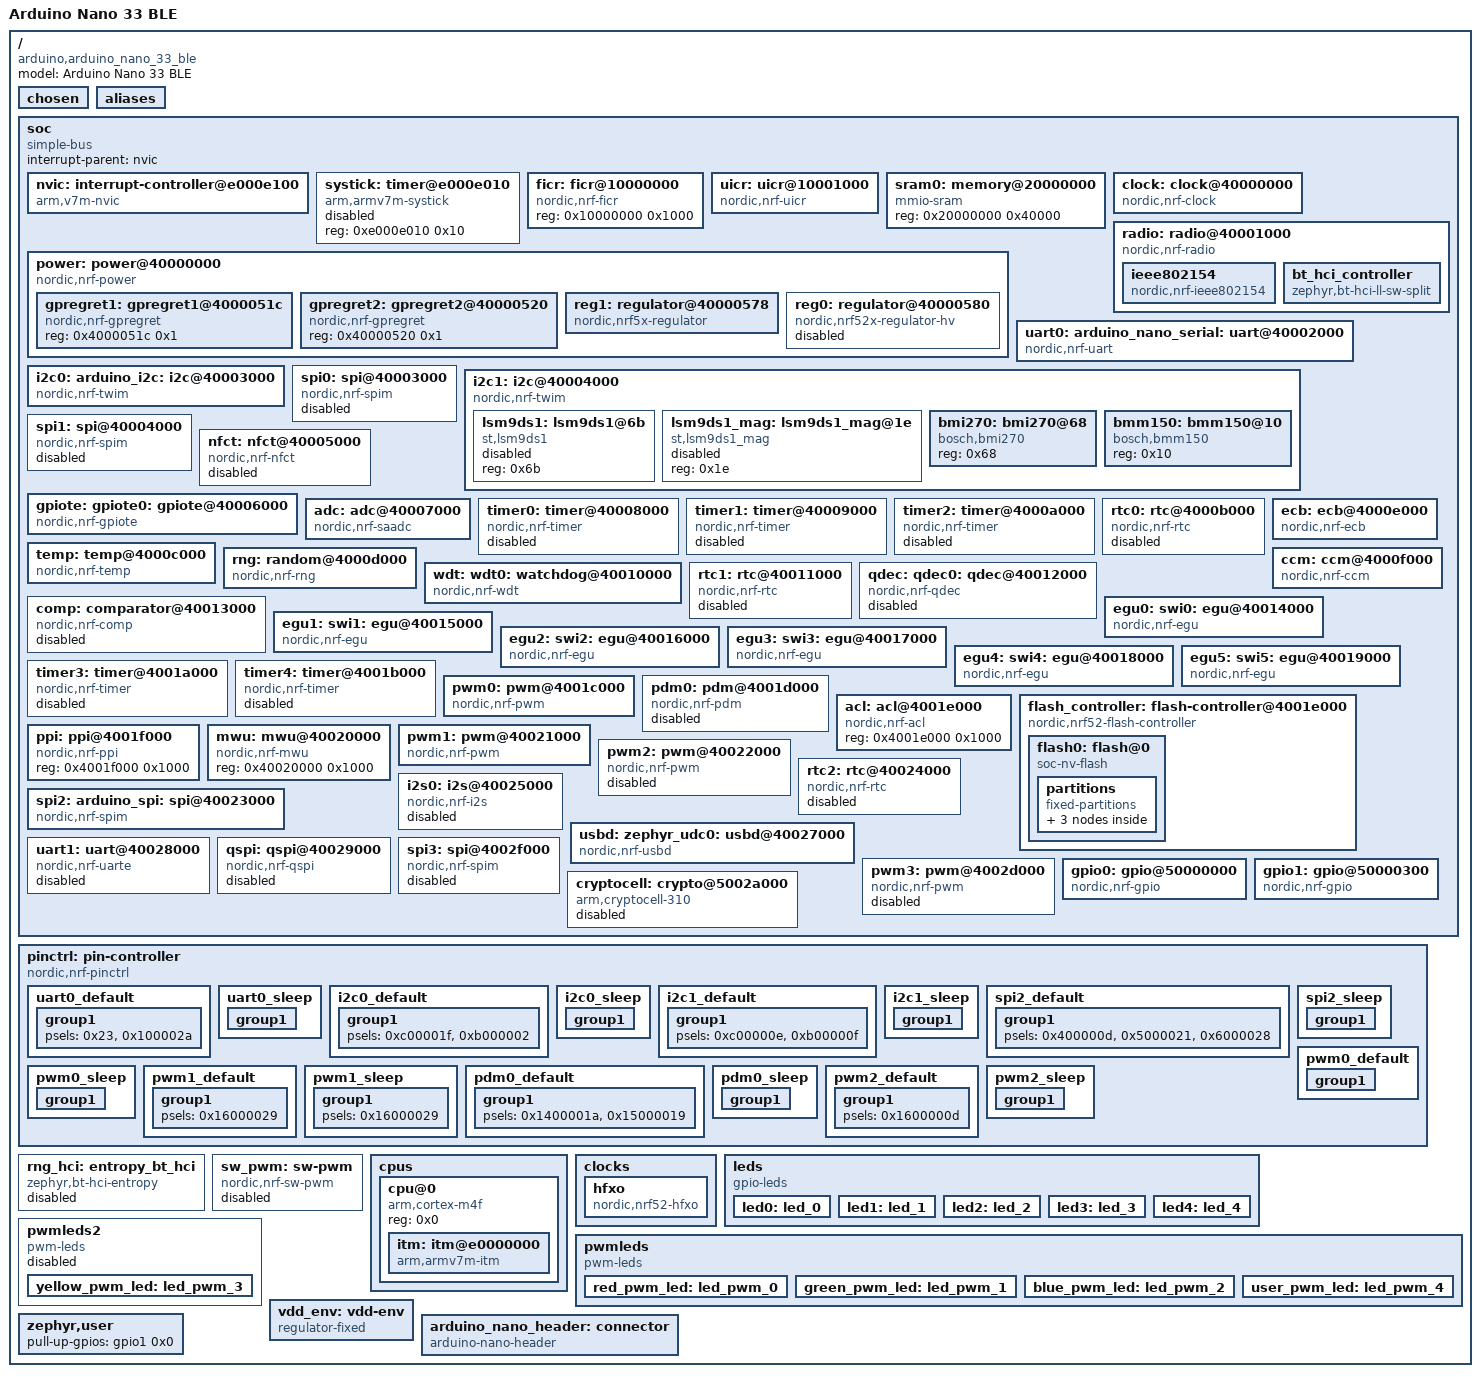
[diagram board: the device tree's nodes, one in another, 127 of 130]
/dts-v1/;

/* node '/' defined in zephyr\dts\common\skeleton.dtsi:9 */
/ {
	#address-cells = < 0x1 >;                   /* in zephyr\dts\common\skeleton.dtsi:10 */
	#size-cells = < 0x1 >;                      /* in zephyr\dts\common\skeleton.dtsi:11 */
	model = "Arduino Nano 33 BLE";              /* in zephyr\boards\arduino\nano_33_ble\arduino_nano_33_ble.dts:13 */
	compatible = "arduino,arduino_nano_33_ble"; /* in zephyr\boards\arduino\nano_33_ble\arduino_nano_33_ble.dts:14 */

	/* node '/chosen' defined in zephyr\dts\common\skeleton.dtsi:13 */
	chosen {
		zephyr,bt-hci = &bt_hci_controller;          /* in zephyr\dts\arm\nordic\nrf52840.dtsi:10 */
		zephyr,entropy = &rng;                       /* in zephyr\dts\arm\nordic\nrf52840.dtsi:11 */
		zephyr,flash-controller = &flash_controller; /* in zephyr\dts\arm\nordic\nrf52840.dtsi:12 */
		zephyr,console = &uart0;                     /* in zephyr\boards\arduino\nano_33_ble\arduino_nano_33_ble-common.dtsi:9 */
		zephyr,shell-uart = &uart0;                  /* in zephyr\boards\arduino\nano_33_ble\arduino_nano_33_ble-common.dtsi:10 */
		zephyr,uart-mcumgr = &uart0;                 /* in zephyr\boards\arduino\nano_33_ble\arduino_nano_33_ble-common.dtsi:11 */
		zephyr,bt-mon-uart = &uart0;                 /* in zephyr\boards\arduino\nano_33_ble\arduino_nano_33_ble-common.dtsi:12 */
		zephyr,bt-c2h-uart = &uart0;                 /* in zephyr\boards\arduino\nano_33_ble\arduino_nano_33_ble-common.dtsi:13 */
		zephyr,sram = &sram0;                        /* in zephyr\boards\arduino\nano_33_ble\arduino_nano_33_ble-common.dtsi:14 */
		zephyr,flash = &flash0;                      /* in zephyr\boards\arduino\nano_33_ble\arduino_nano_33_ble-common.dtsi:15 */
		zephyr,code-partition = &code_partition;     /* in zephyr\boards\arduino\nano_33_ble\arduino_nano_33_ble-common.dtsi:16 */
		zephyr,ieee802154 = &ieee802154;             /* in zephyr\boards\arduino\nano_33_ble\arduino_nano_33_ble-common.dtsi:17 */
	};

	/* node '/aliases' defined in zephyr\dts\common\skeleton.dtsi:15 */
	aliases {
		led0 = &led0;                   /* in zephyr\boards\arduino\nano_33_ble\arduino_nano_33_ble-common.dtsi:100 */
		led1 = &led1;                   /* in zephyr\boards\arduino\nano_33_ble\arduino_nano_33_ble-common.dtsi:101 */
		led2 = &led2;                   /* in zephyr\boards\arduino\nano_33_ble\arduino_nano_33_ble-common.dtsi:102 */
		led3 = &led3;                   /* in zephyr\boards\arduino\nano_33_ble\arduino_nano_33_ble-common.dtsi:103 */
		led4 = &led4;                   /* in zephyr\boards\arduino\nano_33_ble\arduino_nano_33_ble-common.dtsi:104 */
		pwm-led0 = &red_pwm_led;        /* in zephyr\boards\arduino\nano_33_ble\arduino_nano_33_ble-common.dtsi:105 */
		pwm-led1 = &green_pwm_led;      /* in zephyr\boards\arduino\nano_33_ble\arduino_nano_33_ble-common.dtsi:106 */
		pwm-led2 = &blue_pwm_led;       /* in zephyr\boards\arduino\nano_33_ble\arduino_nano_33_ble-common.dtsi:107 */
		pwm-led3 = &yellow_pwm_led;     /* in zephyr\boards\arduino\nano_33_ble\arduino_nano_33_ble-common.dtsi:108 */
		pwm-led4 = &user_pwm_led;       /* in zephyr\boards\arduino\nano_33_ble\arduino_nano_33_ble-common.dtsi:109 */
		red-pwm-led = &red_pwm_led;     /* in zephyr\boards\arduino\nano_33_ble\arduino_nano_33_ble-common.dtsi:110 */
		green-pwm-led = &green_pwm_led; /* in zephyr\boards\arduino\nano_33_ble\arduino_nano_33_ble-common.dtsi:111 */
		blue-pwm-led = &blue_pwm_led;   /* in zephyr\boards\arduino\nano_33_ble\arduino_nano_33_ble-common.dtsi:112 */
		spi = &spi2;                    /* in zephyr\boards\arduino\nano_33_ble\arduino_nano_33_ble-common.dtsi:113 */
		watchdog0 = &wdt0;              /* in zephyr\boards\arduino\nano_33_ble\arduino_nano_33_ble-common.dtsi:114 */
		accel0 = &lsm9ds1;              /* in zephyr\boards\arduino\nano_33_ble\arduino_nano_33_ble-common.dtsi:115 */
	};

	/* node '/soc' defined in zephyr\dts\arm\armv7-m.dtsi:6 */
	soc {
		#address-cells = < 0x1 >;     /* in zephyr\dts\arm\armv7-m.dtsi:7 */
		#size-cells = < 0x1 >;        /* in zephyr\dts\arm\armv7-m.dtsi:8 */
		interrupt-parent = < &nvic >; /* in zephyr\dts\arm\armv7-m.dtsi:10 */
		ranges;                       /* in zephyr\dts\arm\armv7-m.dtsi:11 */
		compatible = "simple-bus";    /* in zephyr\dts\arm\nordic\nrf52840_qiaa.dtsi:30 */

		/* node '/soc/interrupt-controller@e000e100' defined in zephyr\dts\arm\armv7-m.dtsi:13 */
		nvic: interrupt-controller@e000e100 {
			#address-cells = < 0x1 >;            /* in zephyr\dts\arm\armv7-m.dtsi:14 */
			compatible = "arm,v7m-nvic";         /* in zephyr\dts\arm\armv7-m.dtsi:15 */
			reg = < 0xe000e100 0xc00 >;          /* in zephyr\dts\arm\armv7-m.dtsi:16 */
			interrupt-controller;                /* in zephyr\dts\arm\armv7-m.dtsi:17 */
			#interrupt-cells = < 0x2 >;          /* in zephyr\dts\arm\armv7-m.dtsi:18 */
			arm,num-irq-priority-bits = < 0x3 >; /* in zephyr\dts\arm\nordic\nrf52840.dtsi:582 */
			phandle = < 0x1 >;                   /* in zephyr\dts\arm\armv7-m.dtsi:10 */
		};

		/* node '/soc/timer@e000e010' defined in zephyr\dts\arm\armv7-m.dtsi:21 */
		systick: timer@e000e010 {
			compatible = "arm,armv7m-systick"; /* in zephyr\dts\arm\armv7-m.dtsi:22 */
			reg = < 0xe000e010 0x10 >;         /* in zephyr\dts\arm\armv7-m.dtsi:23 */
			status = "disabled";               /* in zephyr\dts\arm\nordic\nrf52840.dtsi:587 */
		};

		/* node '/soc/ficr@10000000' defined in zephyr\dts\arm\nordic\nrf52840.dtsi:44 */
		ficr: ficr@10000000 {
			compatible = "nordic,nrf-ficr"; /* in zephyr\dts\arm\nordic\nrf52840.dtsi:45 */
			reg = < 0x10000000 0x1000 >;    /* in zephyr\dts\arm\nordic\nrf52840.dtsi:46 */
			#nordic,ficr-cells = < 0x1 >;   /* in zephyr\dts\arm\nordic\nrf52840.dtsi:47 */
			status = "okay";                /* in zephyr\dts\arm\nordic\nrf52840.dtsi:48 */
		};

		/* node '/soc/uicr@10001000' defined in zephyr\dts\arm\nordic\nrf52840.dtsi:51 */
		uicr: uicr@10001000 {
			compatible = "nordic,nrf-uicr"; /* in zephyr\dts\arm\nordic\nrf52840.dtsi:52 */
			reg = < 0x10001000 0x1000 >;    /* in zephyr\dts\arm\nordic\nrf52840.dtsi:53 */
			status = "okay";                /* in zephyr\dts\arm\nordic\nrf52840.dtsi:54 */
			gpio-as-nreset;                 /* in zephyr\boards\arduino\nano_33_ble\arduino_nano_33_ble-common.dtsi:200 */
		};

		/* node '/soc/memory@20000000' defined in zephyr\dts\arm\nordic\nrf52840.dtsi:57 */
		sram0: memory@20000000 {
			compatible = "mmio-sram";            /* in zephyr\dts\arm\nordic\nrf52840.dtsi:58 */
			#address-cells = < 0x1 >;            /* in zephyr\dts\arm\nordic\nrf52840.dtsi:59 */
			#size-cells = < 0x1 >;               /* in zephyr\dts\arm\nordic\nrf52840.dtsi:60 */
			reg = < 0x20000000 0x40000 >;        /* in zephyr\dts\arm\nordic\nrf52840_qiaa.dtsi:15 */
			ranges = < 0x0 0x20000000 0x40000 >; /* in zephyr\dts\arm\nordic\nrf52840_qiaa.dtsi:16 */
		};

		/* node '/soc/clock@40000000' defined in zephyr\dts\arm\nordic\nrf52840.dtsi:63 */
		clock: clock@40000000 {
			compatible = "nordic,nrf-clock"; /* in zephyr\dts\arm\nordic\nrf52840.dtsi:64 */
			reg = < 0x40000000 0x1000 >;     /* in zephyr\dts\arm\nordic\nrf52840.dtsi:65 */
			interrupts = < 0x0 0x1 >;        /* in zephyr\dts\arm\nordic\nrf52840.dtsi:66 */
			status = "okay";                 /* in zephyr\dts\arm\nordic\nrf52840.dtsi:67 */
		};

		/* node '/soc/power@40000000' defined in zephyr\dts\arm\nordic\nrf52840.dtsi:70 */
		power: power@40000000 {
			compatible = "nordic,nrf-power"; /* in zephyr\dts\arm\nordic\nrf52840.dtsi:71 */
			reg = < 0x40000000 0x1000 >;     /* in zephyr\dts\arm\nordic\nrf52840.dtsi:72 */
			interrupts = < 0x0 0x1 >;        /* in zephyr\dts\arm\nordic\nrf52840.dtsi:73 */
			status = "okay";                 /* in zephyr\dts\arm\nordic\nrf52840.dtsi:74 */
			#address-cells = < 0x1 >;        /* in zephyr\dts\arm\nordic\nrf52840.dtsi:75 */
			#size-cells = < 0x1 >;           /* in zephyr\dts\arm\nordic\nrf52840.dtsi:76 */

			/* node '/soc/power@40000000/gpregret1@4000051c' defined in zephyr\dts\arm\nordic\nrf52840.dtsi:78 */
			gpregret1: gpregret1@4000051c {
				#address-cells = < 0x1 >;           /* in zephyr\dts\arm\nordic\nrf52840.dtsi:79 */
				#size-cells = < 0x1 >;              /* in zephyr\dts\arm\nordic\nrf52840.dtsi:80 */
				compatible = "nordic,nrf-gpregret"; /* in zephyr\dts\arm\nordic\nrf52840.dtsi:81 */
				reg = < 0x4000051c 0x1 >;           /* in zephyr\dts\arm\nordic\nrf52840.dtsi:82 */
				status = "okay";                    /* in zephyr\dts\arm\nordic\nrf52840.dtsi:83 */
			};

			/* node '/soc/power@40000000/gpregret2@40000520' defined in zephyr\dts\arm\nordic\nrf52840.dtsi:86 */
			gpregret2: gpregret2@40000520 {
				#address-cells = < 0x1 >;           /* in zephyr\dts\arm\nordic\nrf52840.dtsi:87 */
				#size-cells = < 0x1 >;              /* in zephyr\dts\arm\nordic\nrf52840.dtsi:88 */
				compatible = "nordic,nrf-gpregret"; /* in zephyr\dts\arm\nordic\nrf52840.dtsi:89 */
				reg = < 0x40000520 0x1 >;           /* in zephyr\dts\arm\nordic\nrf52840.dtsi:90 */
				status = "okay";                    /* in zephyr\dts\arm\nordic\nrf52840.dtsi:91 */
			};

			/* node '/soc/power@40000000/regulator@40000578' defined in zephyr\dts\arm\nordic\nrf52840.dtsi:94 */
			reg1: regulator@40000578 {
				compatible = "nordic,nrf5x-regulator"; /* in zephyr\dts\arm\nordic\nrf52840.dtsi:95 */
				reg = < 0x40000578 0x1 >;              /* in zephyr\dts\arm\nordic\nrf52840.dtsi:96 */
				regulator-name = "REG1";               /* in zephyr\dts\arm\nordic\nrf52840.dtsi:97 */
				regulator-initial-mode = < 0x0 >;      /* in zephyr\dts\arm\nordic\nrf52840.dtsi:98 */
			};

			/* node '/soc/power@40000000/regulator@40000580' defined in zephyr\dts\arm\nordic\nrf52840_qiaa.dtsi:20 */
			reg0: regulator@40000580 {
				compatible = "nordic,nrf52x-regulator-hv"; /* in zephyr\dts\arm\nordic\nrf52840_qiaa.dtsi:21 */
				reg = < 0x40000580 0x1 >;                  /* in zephyr\dts\arm\nordic\nrf52840_qiaa.dtsi:22 */
				regulator-name = "REG0";                   /* in zephyr\dts\arm\nordic\nrf52840_qiaa.dtsi:23 */
				status = "disabled";                       /* in zephyr\dts\arm\nordic\nrf52840_qiaa.dtsi:24 */
			};
		};

		/* node '/soc/radio@40001000' defined in zephyr\dts\arm\nordic\nrf52840.dtsi:102 */
		radio: radio@40001000 {
			compatible = "nordic,nrf-radio"; /* in zephyr\dts\arm\nordic\nrf52840.dtsi:103 */
			reg = < 0x40001000 0x1000 >;     /* in zephyr\dts\arm\nordic\nrf52840.dtsi:104 */
			interrupts = < 0x1 0x1 >;        /* in zephyr\dts\arm\nordic\nrf52840.dtsi:105 */
			status = "okay";                 /* in zephyr\dts\arm\nordic\nrf52840.dtsi:106 */
			ieee802154-supported;            /* in zephyr\dts\arm\nordic\nrf52840.dtsi:107 */
			ble-2mbps-supported;             /* in zephyr\dts\arm\nordic\nrf52840.dtsi:108 */
			ble-coded-phy-supported;         /* in zephyr\dts\arm\nordic\nrf52840.dtsi:109 */
			tx-high-power-supported;         /* in zephyr\dts\arm\nordic\nrf52840.dtsi:110 */

			/* node '/soc/radio@40001000/ieee802154' defined in zephyr\dts\arm\nordic\nrf52840.dtsi:112 */
			ieee802154: ieee802154 {
				compatible = "nordic,nrf-ieee802154"; /* in zephyr\dts\arm\nordic\nrf52840.dtsi:113 */
				status = "okay";                      /* in zephyr\boards\arduino\nano_33_ble\arduino_nano_33_ble-common.dtsi:243 */
			};

			/* node '/soc/radio@40001000/bt_hci_controller' defined in zephyr\dts\arm\nordic\nrf52840.dtsi:120 */
			bt_hci_controller: bt_hci_controller {
				compatible = "zephyr,bt-hci-ll-sw-split"; /* in zephyr\dts\arm\nordic\nrf52840.dtsi:121 */
				status = "okay";                          /* in zephyr\dts\arm\nordic\nrf52840.dtsi:122 */
			};
		};

		/* node '/soc/uart@40002000' defined in zephyr\dts\arm\nordic\nrf52840.dtsi:126 */
		uart0: arduino_nano_serial: uart@40002000 {
			reg = < 0x40002000 0x1000 >;    /* in zephyr\dts\arm\nordic\nrf52840.dtsi:130 */
			interrupts = < 0x2 0x1 >;       /* in zephyr\dts\arm\nordic\nrf52840.dtsi:131 */
			compatible = "nordic,nrf-uart"; /* in zephyr\boards\arduino\nano_33_ble\arduino_nano_33_ble-common.dtsi:156 */
			current-speed = < 0x1c200 >;    /* in zephyr\boards\arduino\nano_33_ble\arduino_nano_33_ble-common.dtsi:157 */
			status = "okay";                /* in zephyr\boards\arduino\nano_33_ble\arduino_nano_33_ble-common.dtsi:158 */
			pinctrl-0 = < &uart0_default >; /* in zephyr\boards\arduino\nano_33_ble\arduino_nano_33_ble-common.dtsi:159 */
			pinctrl-1 = < &uart0_sleep >;   /* in zephyr\boards\arduino\nano_33_ble\arduino_nano_33_ble-common.dtsi:160 */
			pinctrl-names = "default",
			                "sleep";        /* in zephyr\boards\arduino\nano_33_ble\arduino_nano_33_ble-common.dtsi:161 */
		};

		/* node '/soc/i2c@40003000' defined in zephyr\dts\arm\nordic\nrf52840.dtsi:135 */
		i2c0: arduino_i2c: arduino_nano_i2c: i2c@40003000 {
			#address-cells = < 0x1 >;       /* in zephyr\dts\arm\nordic\nrf52840.dtsi:144 */
			#size-cells = < 0x0 >;          /* in zephyr\dts\arm\nordic\nrf52840.dtsi:145 */
			reg = < 0x40003000 0x1000 >;    /* in zephyr\dts\arm\nordic\nrf52840.dtsi:146 */
			interrupts = < 0x3 0x1 >;       /* in zephyr\dts\arm\nordic\nrf52840.dtsi:147 */
			easydma-maxcnt-bits = < 0x10 >; /* in zephyr\dts\arm\nordic\nrf52840.dtsi:148 */
			zephyr,pm-device-runtime-auto;  /* in zephyr\dts\arm\nordic\nrf52840.dtsi:150 */
			compatible = "nordic,nrf-twim"; /* in zephyr\boards\arduino\nano_33_ble\arduino_nano_33_ble-common.dtsi:165 */
			status = "okay";                /* in zephyr\boards\arduino\nano_33_ble\arduino_nano_33_ble-common.dtsi:166 */
			pinctrl-0 = < &i2c0_default >;  /* in zephyr\boards\arduino\nano_33_ble\arduino_nano_33_ble-common.dtsi:167 */
			pinctrl-1 = < &i2c0_sleep >;    /* in zephyr\boards\arduino\nano_33_ble\arduino_nano_33_ble-common.dtsi:168 */
			pinctrl-names = "default",
			                "sleep";        /* in zephyr\boards\arduino\nano_33_ble\arduino_nano_33_ble-common.dtsi:169 */
		};

		/* node '/soc/spi@40003000' defined in zephyr\dts\arm\nordic\nrf52840.dtsi:153 */
		spi0: spi@40003000 {
			compatible = "nordic,nrf-spim"; /* in zephyr\dts\arm\nordic\nrf52840.dtsi:161 */
			#address-cells = < 0x1 >;       /* in zephyr\dts\arm\nordic\nrf52840.dtsi:162 */
			#size-cells = < 0x0 >;          /* in zephyr\dts\arm\nordic\nrf52840.dtsi:163 */
			reg = < 0x40003000 0x1000 >;    /* in zephyr\dts\arm\nordic\nrf52840.dtsi:164 */
			interrupts = < 0x3 0x1 >;       /* in zephyr\dts\arm\nordic\nrf52840.dtsi:165 */
			max-frequency = < 0x7a1200 >;   /* in zephyr\dts\arm\nordic\nrf52840.dtsi:166 */
			easydma-maxcnt-bits = < 0x10 >; /* in zephyr\dts\arm\nordic\nrf52840.dtsi:167 */
			status = "disabled";            /* in zephyr\dts\arm\nordic\nrf52840.dtsi:168 */
		};

		/* node '/soc/i2c@40004000' defined in zephyr\dts\arm\nordic\nrf52840.dtsi:171 */
		i2c1: i2c@40004000 {
			#address-cells = < 0x1 >;       /* in zephyr\dts\arm\nordic\nrf52840.dtsi:180 */
			#size-cells = < 0x0 >;          /* in zephyr\dts\arm\nordic\nrf52840.dtsi:181 */
			reg = < 0x40004000 0x1000 >;    /* in zephyr\dts\arm\nordic\nrf52840.dtsi:182 */
			interrupts = < 0x4 0x1 >;       /* in zephyr\dts\arm\nordic\nrf52840.dtsi:183 */
			easydma-maxcnt-bits = < 0x10 >; /* in zephyr\dts\arm\nordic\nrf52840.dtsi:184 */
			zephyr,pm-device-runtime-auto;  /* in zephyr\dts\arm\nordic\nrf52840.dtsi:186 */
			compatible = "nordic,nrf-twim"; /* in zephyr\boards\arduino\nano_33_ble\arduino_nano_33_ble-common.dtsi:173 */
			status = "okay";                /* in zephyr\boards\arduino\nano_33_ble\arduino_nano_33_ble-common.dtsi:174 */
			pinctrl-0 = < &i2c1_default >;  /* in zephyr\boards\arduino\nano_33_ble\arduino_nano_33_ble-common.dtsi:175 */
			pinctrl-1 = < &i2c1_sleep >;    /* in zephyr\boards\arduino\nano_33_ble\arduino_nano_33_ble-common.dtsi:176 */
			pinctrl-names = "default",
			                "sleep";        /* in zephyr\boards\arduino\nano_33_ble\arduino_nano_33_ble-common.dtsi:177 */

			/* node '/soc/i2c@40004000/lsm9ds1@6b' defined in zephyr\boards\arduino\nano_33_ble\arduino_nano_33_ble-common.dtsi:179 */
			lsm9ds1: lsm9ds1@6b {
				compatible = "st,lsm9ds1"; /* in zephyr\boards\arduino\nano_33_ble\arduino_nano_33_ble-common.dtsi:180 */
				reg = < 0x6b >;            /* in zephyr\boards\arduino\nano_33_ble\arduino_nano_33_ble-common.dtsi:181 */
				status = "disabled";       /* in imu_logger\app.overlay:11 */
			};

			/* node '/soc/i2c@40004000/lsm9ds1_mag@1e' defined in zephyr\boards\arduino\nano_33_ble\arduino_nano_33_ble-common.dtsi:184 */
			lsm9ds1_mag: lsm9ds1_mag@1e {
				compatible = "st,lsm9ds1_mag"; /* in zephyr\boards\arduino\nano_33_ble\arduino_nano_33_ble-common.dtsi:185 */
				reg = < 0x1e >;                /* in zephyr\boards\arduino\nano_33_ble\arduino_nano_33_ble-common.dtsi:186 */
				status = "disabled";           /* in imu_logger\app.overlay:15 */
			};

			/* node '/soc/i2c@40004000/bmi270@68' defined in imu_logger\app.overlay:19 */
			bmi270: bmi270@68 {
				compatible = "bosch,bmi270"; /* in imu_logger\app.overlay:20 */
				reg = < 0x68 >;              /* in imu_logger\app.overlay:21 */
			};

			/* node '/soc/i2c@40004000/bmm150@10' defined in imu_logger\app.overlay:24 */
			bmm150: bmm150@10 {
				compatible = "bosch,bmm150"; /* in imu_logger\app.overlay:25 */
				reg = < 0x10 >;              /* in imu_logger\app.overlay:26 */
			};
		};

		/* node '/soc/spi@40004000' defined in zephyr\dts\arm\nordic\nrf52840.dtsi:189 */
		spi1: spi@40004000 {
			compatible = "nordic,nrf-spim"; /* in zephyr\dts\arm\nordic\nrf52840.dtsi:197 */
			#address-cells = < 0x1 >;       /* in zephyr\dts\arm\nordic\nrf52840.dtsi:198 */
			#size-cells = < 0x0 >;          /* in zephyr\dts\arm\nordic\nrf52840.dtsi:199 */
			reg = < 0x40004000 0x1000 >;    /* in zephyr\dts\arm\nordic\nrf52840.dtsi:200 */
			interrupts = < 0x4 0x1 >;       /* in zephyr\dts\arm\nordic\nrf52840.dtsi:201 */
			max-frequency = < 0x7a1200 >;   /* in zephyr\dts\arm\nordic\nrf52840.dtsi:202 */
			easydma-maxcnt-bits = < 0x10 >; /* in zephyr\dts\arm\nordic\nrf52840.dtsi:203 */
			status = "disabled";            /* in zephyr\dts\arm\nordic\nrf52840.dtsi:204 */
		};

		/* node '/soc/nfct@40005000' defined in zephyr\dts\arm\nordic\nrf52840.dtsi:207 */
		nfct: nfct@40005000 {
			compatible = "nordic,nrf-nfct"; /* in zephyr\dts\arm\nordic\nrf52840.dtsi:208 */
			reg = < 0x40005000 0x1000 >;    /* in zephyr\dts\arm\nordic\nrf52840.dtsi:209 */
			interrupts = < 0x5 0x1 >;       /* in zephyr\dts\arm\nordic\nrf52840.dtsi:210 */
			status = "disabled";            /* in zephyr\dts\arm\nordic\nrf52840.dtsi:211 */
		};

		/* node '/soc/gpiote@40006000' defined in zephyr\dts\arm\nordic\nrf52840.dtsi:214 */
		gpiote: gpiote0: gpiote@40006000 {
			compatible = "nordic,nrf-gpiote"; /* in zephyr\dts\arm\nordic\nrf52840.dtsi:215 */
			reg = < 0x40006000 0x1000 >;      /* in zephyr\dts\arm\nordic\nrf52840.dtsi:216 */
			interrupts = < 0x6 0x5 >;         /* in zephyr\dts\arm\nordic\nrf52840.dtsi:217 */
			instance = < 0x0 >;               /* in zephyr\dts\arm\nordic\nrf52840.dtsi:219 */
			status = "okay";                  /* in zephyr\boards\arduino\nano_33_ble\arduino_nano_33_ble-common.dtsi:212 */
			phandle = < 0x10 >;               /* in zephyr\dts\arm\nordic\nrf52840.dtsi:556 */
		};

		/* node '/soc/adc@40007000' defined in zephyr\dts\arm\nordic\nrf52840.dtsi:222 */
		adc: adc@40007000 {
			compatible = "nordic,nrf-saadc"; /* in zephyr\dts\arm\nordic\nrf52840.dtsi:223 */
			reg = < 0x40007000 0x1000 >;     /* in zephyr\dts\arm\nordic\nrf52840.dtsi:224 */
			interrupts = < 0x7 0x1 >;        /* in zephyr\dts\arm\nordic\nrf52840.dtsi:225 */
			#io-channel-cells = < 0x1 >;     /* in zephyr\dts\arm\nordic\nrf52840.dtsi:227 */
			zephyr,pm-device-runtime-auto;   /* in zephyr\dts\arm\nordic\nrf52840.dtsi:228 */
			status = "okay";                 /* in zephyr\boards\arduino\nano_33_ble\arduino_nano_33_ble-common.dtsi:152 */
		};

		/* node '/soc/timer@40008000' defined in zephyr\dts\arm\nordic\nrf52840.dtsi:231 */
		timer0: timer@40008000 {
			compatible = "nordic,nrf-timer"; /* in zephyr\dts\arm\nordic\nrf52840.dtsi:232 */
			status = "disabled";             /* in zephyr\dts\arm\nordic\nrf52840.dtsi:233 */
			reg = < 0x40008000 0x1000 >;     /* in zephyr\dts\arm\nordic\nrf52840.dtsi:234 */
			cc-num = < 0x4 >;                /* in zephyr\dts\arm\nordic\nrf52840.dtsi:235 */
			max-bit-width = < 0x20 >;        /* in zephyr\dts\arm\nordic\nrf52840.dtsi:236 */
			interrupts = < 0x8 0x1 >;        /* in zephyr\dts\arm\nordic\nrf52840.dtsi:237 */
			prescaler = < 0x0 >;             /* in zephyr\dts\arm\nordic\nrf52840.dtsi:238 */
		};

		/* node '/soc/timer@40009000' defined in zephyr\dts\arm\nordic\nrf52840.dtsi:241 */
		timer1: timer@40009000 {
			compatible = "nordic,nrf-timer"; /* in zephyr\dts\arm\nordic\nrf52840.dtsi:242 */
			status = "disabled";             /* in zephyr\dts\arm\nordic\nrf52840.dtsi:243 */
			reg = < 0x40009000 0x1000 >;     /* in zephyr\dts\arm\nordic\nrf52840.dtsi:244 */
			cc-num = < 0x4 >;                /* in zephyr\dts\arm\nordic\nrf52840.dtsi:245 */
			max-bit-width = < 0x20 >;        /* in zephyr\dts\arm\nordic\nrf52840.dtsi:246 */
			interrupts = < 0x9 0x1 >;        /* in zephyr\dts\arm\nordic\nrf52840.dtsi:247 */
			prescaler = < 0x0 >;             /* in zephyr\dts\arm\nordic\nrf52840.dtsi:248 */
			phandle = < 0x11 >;              /* in zephyr\dts\vendor\nordic\nrf_common.dtsi:42 */
		};

		/* node '/soc/timer@4000a000' defined in zephyr\dts\arm\nordic\nrf52840.dtsi:251 */
		timer2: timer@4000a000 {
			compatible = "nordic,nrf-timer"; /* in zephyr\dts\arm\nordic\nrf52840.dtsi:252 */
			status = "disabled";             /* in zephyr\dts\arm\nordic\nrf52840.dtsi:253 */
			reg = < 0x4000a000 0x1000 >;     /* in zephyr\dts\arm\nordic\nrf52840.dtsi:254 */
			cc-num = < 0x4 >;                /* in zephyr\dts\arm\nordic\nrf52840.dtsi:255 */
			max-bit-width = < 0x20 >;        /* in zephyr\dts\arm\nordic\nrf52840.dtsi:256 */
			interrupts = < 0xa 0x1 >;        /* in zephyr\dts\arm\nordic\nrf52840.dtsi:257 */
			prescaler = < 0x0 >;             /* in zephyr\dts\arm\nordic\nrf52840.dtsi:258 */
		};

		/* node '/soc/rtc@4000b000' defined in zephyr\dts\arm\nordic\nrf52840.dtsi:261 */
		rtc0: rtc@4000b000 {
			compatible = "nordic,nrf-rtc"; /* in zephyr\dts\arm\nordic\nrf52840.dtsi:262 */
			reg = < 0x4000b000 0x1000 >;   /* in zephyr\dts\arm\nordic\nrf52840.dtsi:263 */
			cc-num = < 0x3 >;              /* in zephyr\dts\arm\nordic\nrf52840.dtsi:264 */
			interrupts = < 0xb 0x1 >;      /* in zephyr\dts\arm\nordic\nrf52840.dtsi:265 */
			status = "disabled";           /* in zephyr\dts\arm\nordic\nrf52840.dtsi:266 */
			clock-frequency = < 0x8000 >;  /* in zephyr\dts\arm\nordic\nrf52840.dtsi:267 */
			prescaler = < 0x1 >;           /* in zephyr\dts\arm\nordic\nrf52840.dtsi:268 */
		};

		/* node '/soc/temp@4000c000' defined in zephyr\dts\arm\nordic\nrf52840.dtsi:271 */
		temp: temp@4000c000 {
			compatible = "nordic,nrf-temp"; /* in zephyr\dts\arm\nordic\nrf52840.dtsi:272 */
			reg = < 0x4000c000 0x1000 >;    /* in zephyr\dts\arm\nordic\nrf52840.dtsi:273 */
			interrupts = < 0xc 0x1 >;       /* in zephyr\dts\arm\nordic\nrf52840.dtsi:274 */
			status = "okay";                /* in zephyr\dts\arm\nordic\nrf52840.dtsi:275 */
		};

		/* node '/soc/random@4000d000' defined in zephyr\dts\arm\nordic\nrf52840.dtsi:278 */
		rng: random@4000d000 {
			compatible = "nordic,nrf-rng"; /* in zephyr\dts\arm\nordic\nrf52840.dtsi:279 */
			reg = < 0x4000d000 0x1000 >;   /* in zephyr\dts\arm\nordic\nrf52840.dtsi:280 */
			interrupts = < 0xd 0x1 >;      /* in zephyr\dts\arm\nordic\nrf52840.dtsi:281 */
			status = "okay";               /* in zephyr\dts\arm\nordic\nrf52840.dtsi:282 */
		};

		/* node '/soc/ecb@4000e000' defined in zephyr\dts\arm\nordic\nrf52840.dtsi:285 */
		ecb: ecb@4000e000 {
			compatible = "nordic,nrf-ecb"; /* in zephyr\dts\arm\nordic\nrf52840.dtsi:286 */
			reg = < 0x4000e000 0x1000 >;   /* in zephyr\dts\arm\nordic\nrf52840.dtsi:287 */
			interrupts = < 0xe 0x1 >;      /* in zephyr\dts\arm\nordic\nrf52840.dtsi:288 */
			status = "okay";               /* in zephyr\dts\arm\nordic\nrf52840.dtsi:289 */
		};

		/* node '/soc/ccm@4000f000' defined in zephyr\dts\arm\nordic\nrf52840.dtsi:292 */
		ccm: ccm@4000f000 {
			compatible = "nordic,nrf-ccm"; /* in zephyr\dts\arm\nordic\nrf52840.dtsi:293 */
			reg = < 0x4000f000 0x1000 >;   /* in zephyr\dts\arm\nordic\nrf52840.dtsi:294 */
			interrupts = < 0xf 0x1 >;      /* in zephyr\dts\arm\nordic\nrf52840.dtsi:295 */
			length-field-length-8-bits;    /* in zephyr\dts\arm\nordic\nrf52840.dtsi:296 */
			status = "okay";               /* in zephyr\dts\arm\nordic\nrf52840.dtsi:297 */
		};

		/* node '/soc/watchdog@40010000' defined in zephyr\dts\arm\nordic\nrf52840.dtsi:300 */
		wdt: wdt0: watchdog@40010000 {
			compatible = "nordic,nrf-wdt"; /* in zephyr\dts\arm\nordic\nrf52840.dtsi:301 */
			reg = < 0x40010000 0x1000 >;   /* in zephyr\dts\arm\nordic\nrf52840.dtsi:302 */
			interrupts = < 0x10 0x1 >;     /* in zephyr\dts\arm\nordic\nrf52840.dtsi:303 */
			status = "okay";               /* in zephyr\dts\arm\nordic\nrf52840.dtsi:304 */
		};

		/* node '/soc/rtc@40011000' defined in zephyr\dts\arm\nordic\nrf52840.dtsi:307 */
		rtc1: rtc@40011000 {
			compatible = "nordic,nrf-rtc"; /* in zephyr\dts\arm\nordic\nrf52840.dtsi:308 */
			reg = < 0x40011000 0x1000 >;   /* in zephyr\dts\arm\nordic\nrf52840.dtsi:309 */
			cc-num = < 0x4 >;              /* in zephyr\dts\arm\nordic\nrf52840.dtsi:310 */
			interrupts = < 0x11 0x1 >;     /* in zephyr\dts\arm\nordic\nrf52840.dtsi:311 */
			status = "disabled";           /* in zephyr\dts\arm\nordic\nrf52840.dtsi:312 */
			clock-frequency = < 0x8000 >;  /* in zephyr\dts\arm\nordic\nrf52840.dtsi:313 */
			prescaler = < 0x1 >;           /* in zephyr\dts\arm\nordic\nrf52840.dtsi:314 */
		};

		/* node '/soc/qdec@40012000' defined in zephyr\dts\arm\nordic\nrf52840.dtsi:317 */
		qdec: qdec0: qdec@40012000 {
			compatible = "nordic,nrf-qdec"; /* in zephyr\dts\arm\nordic\nrf52840.dtsi:318 */
			reg = < 0x40012000 0x1000 >;    /* in zephyr\dts\arm\nordic\nrf52840.dtsi:319 */
			interrupts = < 0x12 0x1 >;      /* in zephyr\dts\arm\nordic\nrf52840.dtsi:320 */
			status = "disabled";            /* in zephyr\dts\arm\nordic\nrf52840.dtsi:321 */
		};

		/* node '/soc/comparator@40013000' defined in zephyr\dts\arm\nordic\nrf52840.dtsi:324 */
		comp: comparator@40013000 {
			compatible = "nordic,nrf-comp"; /* in zephyr\dts\arm\nordic\nrf52840.dtsi:329 */
			reg = < 0x40013000 0x1000 >;    /* in zephyr\dts\arm\nordic\nrf52840.dtsi:330 */
			interrupts = < 0x13 0x1 >;      /* in zephyr\dts\arm\nordic\nrf52840.dtsi:331 */
			status = "disabled";            /* in zephyr\dts\arm\nordic\nrf52840.dtsi:332 */
		};

		/* node '/soc/egu@40014000' defined in zephyr\dts\arm\nordic\nrf52840.dtsi:335 */
		egu0: swi0: egu@40014000 {
			compatible = "nordic,nrf-egu",
			             "nordic,nrf-swi"; /* in zephyr\dts\arm\nordic\nrf52840.dtsi:336 */
			reg = < 0x40014000 0x1000 >;   /* in zephyr\dts\arm\nordic\nrf52840.dtsi:337 */
			interrupts = < 0x14 0x1 >;     /* in zephyr\dts\arm\nordic\nrf52840.dtsi:338 */
			status = "okay";               /* in zephyr\dts\arm\nordic\nrf52840.dtsi:339 */
		};

		/* node '/soc/egu@40015000' defined in zephyr\dts\arm\nordic\nrf52840.dtsi:342 */
		egu1: swi1: egu@40015000 {
			compatible = "nordic,nrf-egu",
			             "nordic,nrf-swi"; /* in zephyr\dts\arm\nordic\nrf52840.dtsi:343 */
			reg = < 0x40015000 0x1000 >;   /* in zephyr\dts\arm\nordic\nrf52840.dtsi:344 */
			interrupts = < 0x15 0x1 >;     /* in zephyr\dts\arm\nordic\nrf52840.dtsi:345 */
			status = "okay";               /* in zephyr\dts\arm\nordic\nrf52840.dtsi:346 */
		};

		/* node '/soc/egu@40016000' defined in zephyr\dts\arm\nordic\nrf52840.dtsi:349 */
		egu2: swi2: egu@40016000 {
			compatible = "nordic,nrf-egu",
			             "nordic,nrf-swi"; /* in zephyr\dts\arm\nordic\nrf52840.dtsi:350 */
			reg = < 0x40016000 0x1000 >;   /* in zephyr\dts\arm\nordic\nrf52840.dtsi:351 */
			interrupts = < 0x16 0x1 >;     /* in zephyr\dts\arm\nordic\nrf52840.dtsi:352 */
			status = "okay";               /* in zephyr\dts\arm\nordic\nrf52840.dtsi:353 */
		};

		/* node '/soc/egu@40017000' defined in zephyr\dts\arm\nordic\nrf52840.dtsi:356 */
		egu3: swi3: egu@40017000 {
			compatible = "nordic,nrf-egu",
			             "nordic,nrf-swi"; /* in zephyr\dts\arm\nordic\nrf52840.dtsi:357 */
			reg = < 0x40017000 0x1000 >;   /* in zephyr\dts\arm\nordic\nrf52840.dtsi:358 */
			interrupts = < 0x17 0x1 >;     /* in zephyr\dts\arm\nordic\nrf52840.dtsi:359 */
			status = "okay";               /* in zephyr\dts\arm\nordic\nrf52840.dtsi:360 */
		};

		/* node '/soc/egu@40018000' defined in zephyr\dts\arm\nordic\nrf52840.dtsi:363 */
		egu4: swi4: egu@40018000 {
			compatible = "nordic,nrf-egu",
			             "nordic,nrf-swi"; /* in zephyr\dts\arm\nordic\nrf52840.dtsi:364 */
			reg = < 0x40018000 0x1000 >;   /* in zephyr\dts\arm\nordic\nrf52840.dtsi:365 */
			interrupts = < 0x18 0x1 >;     /* in zephyr\dts\arm\nordic\nrf52840.dtsi:366 */
			status = "okay";               /* in zephyr\dts\arm\nordic\nrf52840.dtsi:367 */
		};

		/* node '/soc/egu@40019000' defined in zephyr\dts\arm\nordic\nrf52840.dtsi:370 */
		egu5: swi5: egu@40019000 {
			compatible = "nordic,nrf-egu",
			             "nordic,nrf-swi"; /* in zephyr\dts\arm\nordic\nrf52840.dtsi:371 */
			reg = < 0x40019000 0x1000 >;   /* in zephyr\dts\arm\nordic\nrf52840.dtsi:372 */
			interrupts = < 0x19 0x1 >;     /* in zephyr\dts\arm\nordic\nrf52840.dtsi:373 */
			status = "okay";               /* in zephyr\dts\arm\nordic\nrf52840.dtsi:374 */
		};

		/* node '/soc/timer@4001a000' defined in zephyr\dts\arm\nordic\nrf52840.dtsi:377 */
		timer3: timer@4001a000 {
			compatible = "nordic,nrf-timer"; /* in zephyr\dts\arm\nordic\nrf52840.dtsi:378 */
			status = "disabled";             /* in zephyr\dts\arm\nordic\nrf52840.dtsi:379 */
			reg = < 0x4001a000 0x1000 >;     /* in zephyr\dts\arm\nordic\nrf52840.dtsi:380 */
			cc-num = < 0x6 >;                /* in zephyr\dts\arm\nordic\nrf52840.dtsi:381 */
			max-bit-width = < 0x20 >;        /* in zephyr\dts\arm\nordic\nrf52840.dtsi:382 */
			interrupts = < 0x1a 0x1 >;       /* in zephyr\dts\arm\nordic\nrf52840.dtsi:383 */
			prescaler = < 0x0 >;             /* in zephyr\dts\arm\nordic\nrf52840.dtsi:384 */
		};

		/* node '/soc/timer@4001b000' defined in zephyr\dts\arm\nordic\nrf52840.dtsi:387 */
		timer4: timer@4001b000 {
			compatible = "nordic,nrf-timer"; /* in zephyr\dts\arm\nordic\nrf52840.dtsi:388 */
			status = "disabled";             /* in zephyr\dts\arm\nordic\nrf52840.dtsi:389 */
			reg = < 0x4001b000 0x1000 >;     /* in zephyr\dts\arm\nordic\nrf52840.dtsi:390 */
			cc-num = < 0x6 >;                /* in zephyr\dts\arm\nordic\nrf52840.dtsi:391 */
			max-bit-width = < 0x20 >;        /* in zephyr\dts\arm\nordic\nrf52840.dtsi:392 */
			interrupts = < 0x1b 0x1 >;       /* in zephyr\dts\arm\nordic\nrf52840.dtsi:393 */
			prescaler = < 0x0 >;             /* in zephyr\dts\arm\nordic\nrf52840.dtsi:394 */
		};

		/* node '/soc/pwm@4001c000' defined in zephyr\dts\arm\nordic\nrf52840.dtsi:397 */
		pwm0: pwm@4001c000 {
			compatible = "nordic,nrf-pwm"; /* in zephyr\dts\arm\nordic\nrf52840.dtsi:398 */
			reg = < 0x4001c000 0x1000 >;   /* in zephyr\dts\arm\nordic\nrf52840.dtsi:399 */
			interrupts = < 0x1c 0x1 >;     /* in zephyr\dts\arm\nordic\nrf52840.dtsi:400 */
			#pwm-cells = < 0x3 >;          /* in zephyr\dts\arm\nordic\nrf52840.dtsi:402 */
			status = "okay";               /* in zephyr\boards\arduino\nano_33_ble\arduino_nano_33_ble-common.dtsi:216 */
			pinctrl-0 = < &pwm0_default >; /* in zephyr\boards\arduino\nano_33_ble\arduino_nano_33_ble-common.dtsi:217 */
			pinctrl-1 = < &pwm0_sleep >;   /* in zephyr\boards\arduino\nano_33_ble\arduino_nano_33_ble-common.dtsi:218 */
			pinctrl-names = "default",
			                "sleep";       /* in zephyr\boards\arduino\nano_33_ble\arduino_nano_33_ble-common.dtsi:219 */
			phandle = < 0x14 >;            /* in zephyr\boards\arduino\nano_33_ble\arduino_nano_33_ble-common.dtsi:54 */
		};

		/* node '/soc/pdm@4001d000' defined in zephyr\dts\arm\nordic\nrf52840.dtsi:405 */
		pdm0: pdm@4001d000 {
			compatible = "nordic,nrf-pdm"; /* in zephyr\dts\arm\nordic\nrf52840.dtsi:406 */
			reg = < 0x4001d000 0x1000 >;   /* in zephyr\dts\arm\nordic\nrf52840.dtsi:407 */
			interrupts = < 0x1d 0x1 >;     /* in zephyr\dts\arm\nordic\nrf52840.dtsi:408 */
			status = "disabled";           /* in zephyr\dts\arm\nordic\nrf52840.dtsi:409 */
		};

		/* node '/soc/acl@4001e000' defined in zephyr\dts\arm\nordic\nrf52840.dtsi:412 */
		acl: acl@4001e000 {
			compatible = "nordic,nrf-acl"; /* in zephyr\dts\arm\nordic\nrf52840.dtsi:413 */
			reg = < 0x4001e000 0x1000 >;   /* in zephyr\dts\arm\nordic\nrf52840.dtsi:414 */
			status = "okay";               /* in zephyr\dts\arm\nordic\nrf52840.dtsi:415 */
		};

		/* node '/soc/flash-controller@4001e000' defined in zephyr\dts\arm\nordic\nrf52840.dtsi:418 */
		flash_controller: flash-controller@4001e000 {
			compatible = "nordic,nrf52-flash-controller"; /* in zephyr\dts\arm\nordic\nrf52840.dtsi:419 */
			reg = < 0x4001e000 0x1000 >;                  /* in zephyr\dts\arm\nordic\nrf52840.dtsi:420 */
			partial-erase;                                /* in zephyr\dts\arm\nordic\nrf52840.dtsi:421 */
			#address-cells = < 0x1 >;                     /* in zephyr\dts\arm\nordic\nrf52840.dtsi:423 */
			#size-cells = < 0x1 >;                        /* in zephyr\dts\arm\nordic\nrf52840.dtsi:424 */

			/* node '/soc/flash-controller@4001e000/flash@0' defined in zephyr\dts\arm\nordic\nrf52840.dtsi:426 */
			flash0: flash@0 {
				compatible = "soc-nv-flash";   /* in zephyr\dts\arm\nordic\nrf52840.dtsi:427 */
				erase-block-size = < 0x1000 >; /* in zephyr\dts\arm\nordic\nrf52840.dtsi:428 */
				write-block-size = < 0x4 >;    /* in zephyr\dts\arm\nordic\nrf52840.dtsi:429 */
				reg = < 0x0 0x100000 >;        /* in zephyr\dts\arm\nordic\nrf52840_qiaa.dtsi:11 */

				/* node '/soc/flash-controller@4001e000/flash@0/partitions' defined in zephyr\boards\arduino\nano_33_ble\arduino_nano_33_ble-common.dtsi:120 */
				partitions {
					compatible = "fixed-partitions"; /* in zephyr\boards\arduino\nano_33_ble\arduino_nano_33_ble-common.dtsi:121 */
					#address-cells = < 0x1 >;        /* in zephyr\boards\arduino\nano_33_ble\arduino_nano_33_ble-common.dtsi:122 */
					#size-cells = < 0x1 >;           /* in zephyr\boards\arduino\nano_33_ble\arduino_nano_33_ble-common.dtsi:123 */

					/* node '/soc/flash-controller@4001e000/flash@0/partitions/partition@0' defined in zephyr\boards\arduino\nano_33_ble\arduino_nano_33_ble-common.dtsi:125 */
					boot_partition: partition@0 {
						label = "sam-ba";      /* in zephyr\boards\arduino\nano_33_ble\arduino_nano_33_ble-common.dtsi:126 */
						reg = < 0x0 0x10000 >; /* in zephyr\boards\arduino\nano_33_ble\arduino_nano_33_ble-common.dtsi:127 */
						read-only;             /* in zephyr\boards\arduino\nano_33_ble\arduino_nano_33_ble-common.dtsi:128 */
					};

					/* node '/soc/flash-controller@4001e000/flash@0/partitions/partition@10000' defined in zephyr\boards\arduino\nano_33_ble\arduino_nano_33_ble-common.dtsi:131 */
					code_partition: partition@10000 {
						label = "code";            /* in zephyr\boards\arduino\nano_33_ble\arduino_nano_33_ble-common.dtsi:132 */
						reg = < 0x10000 0xe8000 >; /* in zephyr\boards\arduino\nano_33_ble\arduino_nano_33_ble-common.dtsi:133 */
						read-only;                 /* in zephyr\boards\arduino\nano_33_ble\arduino_nano_33_ble-common.dtsi:134 */
					};

					/* node '/soc/flash-controller@4001e000/flash@0/partitions/partition@f8000' defined in zephyr\boards\arduino\nano_33_ble\arduino_nano_33_ble-common.dtsi:144 */
					storage_partition: partition@f8000 {
						label = "storage";        /* in zephyr\boards\arduino\nano_33_ble\arduino_nano_33_ble-common.dtsi:145 */
						reg = < 0xf8000 0x8000 >; /* in zephyr\boards\arduino\nano_33_ble\arduino_nano_33_ble-common.dtsi:146 */
					};
				};
			};
		};

		/* node '/soc/ppi@4001f000' defined in zephyr\dts\arm\nordic\nrf52840.dtsi:433 */
		ppi: ppi@4001f000 {
			compatible = "nordic,nrf-ppi"; /* in zephyr\dts\arm\nordic\nrf52840.dtsi:434 */
			reg = < 0x4001f000 0x1000 >;   /* in zephyr\dts\arm\nordic\nrf52840.dtsi:435 */
			status = "okay";               /* in zephyr\dts\arm\nordic\nrf52840.dtsi:436 */
		};

		/* node '/soc/mwu@40020000' defined in zephyr\dts\arm\nordic\nrf52840.dtsi:439 */
		mwu: mwu@40020000 {
			compatible = "nordic,nrf-mwu"; /* in zephyr\dts\arm\nordic\nrf52840.dtsi:440 */
			reg = < 0x40020000 0x1000 >;   /* in zephyr\dts\arm\nordic\nrf52840.dtsi:441 */
			status = "okay";               /* in zephyr\dts\arm\nordic\nrf52840.dtsi:442 */
		};

		/* node '/soc/pwm@40021000' defined in zephyr\dts\arm\nordic\nrf52840.dtsi:445 */
		pwm1: pwm@40021000 {
			compatible = "nordic,nrf-pwm"; /* in zephyr\dts\arm\nordic\nrf52840.dtsi:446 */
			reg = < 0x40021000 0x1000 >;   /* in zephyr\dts\arm\nordic\nrf52840.dtsi:447 */
			interrupts = < 0x21 0x1 >;     /* in zephyr\dts\arm\nordic\nrf52840.dtsi:448 */
			#pwm-cells = < 0x3 >;          /* in zephyr\dts\arm\nordic\nrf52840.dtsi:450 */
			status = "okay";               /* in zephyr\boards\arduino\nano_33_ble\arduino_nano_33_ble-common.dtsi:223 */
			pinctrl-0 = < &pwm1_default >; /* in zephyr\boards\arduino\nano_33_ble\arduino_nano_33_ble-common.dtsi:224 */
			pinctrl-1 = < &pwm1_sleep >;   /* in zephyr\boards\arduino\nano_33_ble\arduino_nano_33_ble-common.dtsi:225 */
			pinctrl-names = "default",
			                "sleep";       /* in zephyr\boards\arduino\nano_33_ble\arduino_nano_33_ble-common.dtsi:226 */
			phandle = < 0x15 >;            /* in zephyr\boards\arduino\nano_33_ble\arduino_nano_33_ble-common.dtsi:69 */
		};

		/* node '/soc/pwm@40022000' defined in zephyr\dts\arm\nordic\nrf52840.dtsi:453 */
		pwm2: pwm@40022000 {
			compatible = "nordic,nrf-pwm"; /* in zephyr\dts\arm\nordic\nrf52840.dtsi:454 */
			reg = < 0x40022000 0x1000 >;   /* in zephyr\dts\arm\nordic\nrf52840.dtsi:455 */
			interrupts = < 0x22 0x1 >;     /* in zephyr\dts\arm\nordic\nrf52840.dtsi:456 */
			#pwm-cells = < 0x3 >;          /* in zephyr\dts\arm\nordic\nrf52840.dtsi:458 */
			status = "disabled";           /* in zephyr\boards\arduino\nano_33_ble\arduino_nano_33_ble-common.dtsi:231 */
			pinctrl-0 = < &pwm2_default >; /* in zephyr\boards\arduino\nano_33_ble\arduino_nano_33_ble-common.dtsi:232 */
			pinctrl-1 = < &pwm2_sleep >;   /* in zephyr\boards\arduino\nano_33_ble\arduino_nano_33_ble-common.dtsi:233 */
			pinctrl-names = "default",
			                "sleep";       /* in zephyr\boards\arduino\nano_33_ble\arduino_nano_33_ble-common.dtsi:234 */
			phandle = < 0x16 >;            /* in zephyr\boards\arduino\nano_33_ble\arduino_nano_33_ble-common.dtsi:80 */
		};

		/* node '/soc/spi@40023000' defined in zephyr\dts\arm\nordic\nrf52840.dtsi:461 */
		spi2: arduino_spi: arduino_nano_spi: spi@40023000 {
			#address-cells = < 0x1 >;       /* in zephyr\dts\arm\nordic\nrf52840.dtsi:470 */
			#size-cells = < 0x0 >;          /* in zephyr\dts\arm\nordic\nrf52840.dtsi:471 */
			reg = < 0x40023000 0x1000 >;    /* in zephyr\dts\arm\nordic\nrf52840.dtsi:472 */
			interrupts = < 0x23 0x1 >;      /* in zephyr\dts\arm\nordic\nrf52840.dtsi:473 */
			max-frequency = < 0x7a1200 >;   /* in zephyr\dts\arm\nordic\nrf52840.dtsi:474 */
			easydma-maxcnt-bits = < 0x10 >; /* in zephyr\dts\arm\nordic\nrf52840.dtsi:475 */
			compatible = "nordic,nrf-spim"; /* in zephyr\boards\arduino\nano_33_ble\arduino_nano_33_ble-common.dtsi:192 */
			status = "okay";                /* in zephyr\boards\arduino\nano_33_ble\arduino_nano_33_ble-common.dtsi:193 */
			pinctrl-0 = < &spi2_default >;  /* in zephyr\boards\arduino\nano_33_ble\arduino_nano_33_ble-common.dtsi:194 */
			pinctrl-1 = < &spi2_sleep >;    /* in zephyr\boards\arduino\nano_33_ble\arduino_nano_33_ble-common.dtsi:195 */
			pinctrl-names = "default",
			                "sleep";        /* in zephyr\boards\arduino\nano_33_ble\arduino_nano_33_ble-common.dtsi:196 */
		};

		/* node '/soc/rtc@40024000' defined in zephyr\dts\arm\nordic\nrf52840.dtsi:479 */
		rtc2: rtc@40024000 {
			compatible = "nordic,nrf-rtc"; /* in zephyr\dts\arm\nordic\nrf52840.dtsi:480 */
			reg = < 0x40024000 0x1000 >;   /* in zephyr\dts\arm\nordic\nrf52840.dtsi:481 */
			cc-num = < 0x4 >;              /* in zephyr\dts\arm\nordic\nrf52840.dtsi:482 */
			interrupts = < 0x24 0x1 >;     /* in zephyr\dts\arm\nordic\nrf52840.dtsi:483 */
			status = "disabled";           /* in zephyr\dts\arm\nordic\nrf52840.dtsi:484 */
			clock-frequency = < 0x8000 >;  /* in zephyr\dts\arm\nordic\nrf52840.dtsi:485 */
			prescaler = < 0x1 >;           /* in zephyr\dts\arm\nordic\nrf52840.dtsi:486 */
		};

		/* node '/soc/i2s@40025000' defined in zephyr\dts\arm\nordic\nrf52840.dtsi:489 */
		i2s0: i2s@40025000 {
			compatible = "nordic,nrf-i2s"; /* in zephyr\dts\arm\nordic\nrf52840.dtsi:490 */
			#address-cells = < 0x1 >;      /* in zephyr\dts\arm\nordic\nrf52840.dtsi:491 */
			#size-cells = < 0x0 >;         /* in zephyr\dts\arm\nordic\nrf52840.dtsi:492 */
			reg = < 0x40025000 0x1000 >;   /* in zephyr\dts\arm\nordic\nrf52840.dtsi:493 */
			interrupts = < 0x25 0x1 >;     /* in zephyr\dts\arm\nordic\nrf52840.dtsi:494 */
			status = "disabled";           /* in zephyr\dts\arm\nordic\nrf52840.dtsi:495 */
		};

		/* node '/soc/usbd@40027000' defined in zephyr\dts\arm\nordic\nrf52840.dtsi:498 */
		usbd: zephyr_udc0: usbd@40027000 {
			reg = < 0x40027000 0x1000 >;    /* in zephyr\dts\arm\nordic\nrf52840.dtsi:500 */
			interrupts = < 0x27 0x1 >;      /* in zephyr\dts\arm\nordic\nrf52840.dtsi:501 */
			num-bidir-endpoints = < 0x1 >;  /* in zephyr\dts\arm\nordic\nrf52840.dtsi:502 */
			num-in-endpoints = < 0x7 >;     /* in zephyr\dts\arm\nordic\nrf52840.dtsi:503 */
			num-out-endpoints = < 0x7 >;    /* in zephyr\dts\arm\nordic\nrf52840.dtsi:504 */
			num-isoin-endpoints = < 0x1 >;  /* in zephyr\dts\arm\nordic\nrf52840.dtsi:505 */
			num-isoout-endpoints = < 0x1 >; /* in zephyr\dts\arm\nordic\nrf52840.dtsi:506 */
			compatible = "nordic,nrf-usbd"; /* in zephyr\boards\arduino\nano_33_ble\arduino_nano_33_ble-common.dtsi:238 */
			status = "okay";                /* in zephyr\boards\arduino\nano_33_ble\arduino_nano_33_ble-common.dtsi:239 */
		};

		/* node '/soc/uart@40028000' defined in zephyr\dts\arm\nordic\nrf52840.dtsi:510 */
		uart1: uart@40028000 {
			compatible = "nordic,nrf-uarte"; /* in zephyr\dts\arm\nordic\nrf52840.dtsi:511 */
			reg = < 0x40028000 0x1000 >;     /* in zephyr\dts\arm\nordic\nrf52840.dtsi:512 */
			interrupts = < 0x28 0x1 >;       /* in zephyr\dts\arm\nordic\nrf52840.dtsi:513 */
			status = "disabled";             /* in zephyr\dts\arm\nordic\nrf52840.dtsi:514 */
		};

		/* node '/soc/qspi@40029000' defined in zephyr\dts\arm\nordic\nrf52840.dtsi:517 */
		qspi: qspi@40029000 {
			compatible = "nordic,nrf-qspi"; /* in zephyr\dts\arm\nordic\nrf52840.dtsi:518 */
			#address-cells = < 0x1 >;       /* in zephyr\dts\arm\nordic\nrf52840.dtsi:519 */
			#size-cells = < 0x0 >;          /* in zephyr\dts\arm\nordic\nrf52840.dtsi:520 */
			reg = < 0x40029000 0x1000 >,
			      < 0x12000000 0x8000000 >; /* in zephyr\dts\arm\nordic\nrf52840.dtsi:521 */
			reg-names = "qspi",
			            "qspi_mm";          /* in zephyr\dts\arm\nordic\nrf52840.dtsi:522 */
			interrupts = < 0x29 0x1 >;      /* in zephyr\dts\arm\nordic\nrf52840.dtsi:523 */
			status = "disabled";            /* in zephyr\dts\arm\nordic\nrf52840.dtsi:524 */
		};

		/* node '/soc/pwm@4002d000' defined in zephyr\dts\arm\nordic\nrf52840.dtsi:527 */
		pwm3: pwm@4002d000 {
			compatible = "nordic,nrf-pwm"; /* in zephyr\dts\arm\nordic\nrf52840.dtsi:528 */
			reg = < 0x4002d000 0x1000 >;   /* in zephyr\dts\arm\nordic\nrf52840.dtsi:529 */
			interrupts = < 0x2d 0x1 >;     /* in zephyr\dts\arm\nordic\nrf52840.dtsi:530 */
			status = "disabled";           /* in zephyr\dts\arm\nordic\nrf52840.dtsi:531 */
			#pwm-cells = < 0x3 >;          /* in zephyr\dts\arm\nordic\nrf52840.dtsi:532 */
		};

		/* node '/soc/spi@4002f000' defined in zephyr\dts\arm\nordic\nrf52840.dtsi:535 */
		spi3: spi@4002f000 {
			compatible = "nordic,nrf-spim"; /* in zephyr\dts\arm\nordic\nrf52840.dtsi:536 */
			#address-cells = < 0x1 >;       /* in zephyr\dts\arm\nordic\nrf52840.dtsi:537 */
			#size-cells = < 0x0 >;          /* in zephyr\dts\arm\nordic\nrf52840.dtsi:538 */
			reg = < 0x4002f000 0x1000 >;    /* in zephyr\dts\arm\nordic\nrf52840.dtsi:539 */
			interrupts = < 0x2f 0x1 >;      /* in zephyr\dts\arm\nordic\nrf52840.dtsi:540 */
			max-frequency = < 0x1e84800 >;  /* in zephyr\dts\arm\nordic\nrf52840.dtsi:541 */
			easydma-maxcnt-bits = < 0x10 >; /* in zephyr\dts\arm\nordic\nrf52840.dtsi:542 */
			rx-delay-supported;             /* in zephyr\dts\arm\nordic\nrf52840.dtsi:543 */
			rx-delay = < 0x2 >;             /* in zephyr\dts\arm\nordic\nrf52840.dtsi:544 */
			status = "disabled";            /* in zephyr\dts\arm\nordic\nrf52840.dtsi:545 */
		};

		/* node '/soc/gpio@50000000' defined in zephyr\dts\arm\nordic\nrf52840.dtsi:548 */
		gpio0: gpio@50000000 {
			compatible = "nordic,nrf-gpio";              /* in zephyr\dts\arm\nordic\nrf52840.dtsi:549 */
			gpio-controller;                             /* in zephyr\dts\arm\nordic\nrf52840.dtsi:550 */
			reg = < 0x50000000 0x200 0x50000500 0x300 >; /* in zephyr\dts\arm\nordic\nrf52840.dtsi:551 */
			#gpio-cells = < 0x2 >;                       /* in zephyr\dts\arm\nordic\nrf52840.dtsi:553 */
			port = < 0x0 >;                              /* in zephyr\dts\arm\nordic\nrf52840.dtsi:555 */
			gpiote-instance = < &gpiote >;               /* in zephyr\dts\arm\nordic\nrf52840.dtsi:556 */
			status = "okay";                             /* in zephyr\boards\arduino\nano_33_ble\arduino_nano_33_ble-common.dtsi:204 */
			phandle = < 0x12 >;                          /* in zephyr\boards\arduino\nano_33_ble\arduino_nano_33_ble-common.dtsi:24 */
		};

		/* node '/soc/gpio@50000300' defined in zephyr\dts\arm\nordic\nrf52840.dtsi:559 */
		gpio1: gpio@50000300 {
			compatible = "nordic,nrf-gpio";              /* in zephyr\dts\arm\nordic\nrf52840.dtsi:560 */
			gpio-controller;                             /* in zephyr\dts\arm\nordic\nrf52840.dtsi:561 */
			reg = < 0x50000300 0x200 0x50000800 0x300 >; /* in zephyr\dts\arm\nordic\nrf52840.dtsi:562 */
			#gpio-cells = < 0x2 >;                       /* in zephyr\dts\arm\nordic\nrf52840.dtsi:564 */
			ngpios = < 0x10 >;                           /* in zephyr\dts\arm\nordic\nrf52840.dtsi:565 */
			port = < 0x1 >;                              /* in zephyr\dts\arm\nordic\nrf52840.dtsi:567 */
			gpiote-instance = < &gpiote >;               /* in zephyr\dts\arm\nordic\nrf52840.dtsi:568 */
			status = "okay";                             /* in zephyr\boards\arduino\nano_33_ble\arduino_nano_33_ble-common.dtsi:208 */
			phandle = < 0x13 >;                          /* in zephyr\boards\arduino\nano_33_ble\arduino_nano_33_ble-common.dtsi:45 */
		};

		/* node '/soc/crypto@5002a000' defined in zephyr\dts\arm\nordic\nrf52840.dtsi:571 */
		cryptocell: crypto@5002a000 {
			compatible = "arm,cryptocell-310"; /* in zephyr\dts\arm\nordic\nrf52840.dtsi:572 */
			reg = < 0x5002a000 0x1000 >,
			      < 0x5002b000 0x1000 >;       /* in zephyr\dts\arm\nordic\nrf52840.dtsi:573 */
			reg-names = "wrapper",
			            "core";                /* in zephyr\dts\arm\nordic\nrf52840.dtsi:574 */
			interrupts = < 0x2a 0x1 >;         /* in zephyr\dts\arm\nordic\nrf52840.dtsi:575 */
			status = "disabled";               /* in zephyr\dts\arm\nordic\nrf52840.dtsi:576 */
		};
	};

	/* node '/pin-controller' defined in zephyr\dts\vendor\nordic\nrf_common.dtsi:26 */
	pinctrl: pin-controller {
		compatible = "nordic,nrf-pinctrl"; /* in zephyr\dts\vendor\nordic\nrf_common.dtsi:31 */

		/* node '/pin-controller/uart0_default' defined in zephyr\boards\arduino\nano_33_ble\arduino_nano_33_ble-pinctrl.dtsi:7 */
		uart0_default: uart0_default {
			phandle = < 0x2 >; /* in zephyr\boards\arduino\nano_33_ble\arduino_nano_33_ble-common.dtsi:159 */

			/* node '/pin-controller/uart0_default/group1' defined in zephyr\boards\arduino\nano_33_ble\arduino_nano_33_ble-pinctrl.dtsi:8 */
			group1 {
				psels = < 0x23 >,
				        < 0x100002a >; /* in zephyr\boards\arduino\nano_33_ble\arduino_nano_33_ble-pinctrl.dtsi:9 */
			};
		};

		/* node '/pin-controller/uart0_sleep' defined in zephyr\boards\arduino\nano_33_ble\arduino_nano_33_ble-pinctrl.dtsi:14 */
		uart0_sleep: uart0_sleep {
			phandle = < 0x3 >; /* in zephyr\boards\arduino\nano_33_ble\arduino_nano_33_ble-common.dtsi:160 */

			/* node '/pin-controller/uart0_sleep/group1' defined in zephyr\boards\arduino\nano_33_ble\arduino_nano_33_ble-pinctrl.dtsi:15 */
			group1 {
				psels = < 0x23 >,
				        < 0x100002a >; /* in zephyr\boards\arduino\nano_33_ble\arduino_nano_33_ble-pinctrl.dtsi:16 */
				low-power-enable;      /* in zephyr\boards\arduino\nano_33_ble\arduino_nano_33_ble-pinctrl.dtsi:18 */
			};
		};

		/* node '/pin-controller/i2c0_default' defined in zephyr\boards\arduino\nano_33_ble\arduino_nano_33_ble-pinctrl.dtsi:22 */
		i2c0_default: i2c0_default {
			phandle = < 0x4 >; /* in zephyr\boards\arduino\nano_33_ble\arduino_nano_33_ble-common.dtsi:167 */

			/* node '/pin-controller/i2c0_default/group1' defined in zephyr\boards\arduino\nano_33_ble\arduino_nano_33_ble-pinctrl.dtsi:23 */
			group1 {
				psels = < 0xc00001f >,
				        < 0xb000002 >; /* in zephyr\boards\arduino\nano_33_ble\arduino_nano_33_ble-pinctrl.dtsi:24 */
			};
		};

		/* node '/pin-controller/i2c0_sleep' defined in zephyr\boards\arduino\nano_33_ble\arduino_nano_33_ble-pinctrl.dtsi:29 */
		i2c0_sleep: i2c0_sleep {
			phandle = < 0x5 >; /* in zephyr\boards\arduino\nano_33_ble\arduino_nano_33_ble-common.dtsi:168 */

			/* node '/pin-controller/i2c0_sleep/group1' defined in zephyr\boards\arduino\nano_33_ble\arduino_nano_33_ble-pinctrl.dtsi:30 */
			group1 {
				psels = < 0xc00001f >,
				        < 0xb000002 >; /* in zephyr\boards\arduino\nano_33_ble\arduino_nano_33_ble-pinctrl.dtsi:31 */
				low-power-enable;      /* in zephyr\boards\arduino\nano_33_ble\arduino_nano_33_ble-pinctrl.dtsi:33 */
			};
		};

		/* node '/pin-controller/i2c1_default' defined in zephyr\boards\arduino\nano_33_ble\arduino_nano_33_ble-pinctrl.dtsi:37 */
		i2c1_default: i2c1_default {
			phandle = < 0x6 >; /* in zephyr\boards\arduino\nano_33_ble\arduino_nano_33_ble-common.dtsi:175 */

			/* node '/pin-controller/i2c1_default/group1' defined in zephyr\boards\arduino\nano_33_ble\arduino_nano_33_ble-pinctrl.dtsi:38 */
			group1 {
				psels = < 0xc00000e >,
				        < 0xb00000f >; /* in zephyr\boards\arduino\nano_33_ble\arduino_nano_33_ble-pinctrl.dtsi:39 */
			};
		};

		/* node '/pin-controller/i2c1_sleep' defined in zephyr\boards\arduino\nano_33_ble\arduino_nano_33_ble-pinctrl.dtsi:44 */
		i2c1_sleep: i2c1_sleep {
			phandle = < 0x7 >; /* in zephyr\boards\arduino\nano_33_ble\arduino_nano_33_ble-common.dtsi:176 */

			/* node '/pin-controller/i2c1_sleep/group1' defined in zephyr\boards\arduino\nano_33_ble\arduino_nano_33_ble-pinctrl.dtsi:45 */
			group1 {
				psels = < 0xc00000e >,
				        < 0xb00000f >; /* in zephyr\boards\arduino\nano_33_ble\arduino_nano_33_ble-pinctrl.dtsi:46 */
				low-power-enable;      /* in zephyr\boards\arduino\nano_33_ble\arduino_nano_33_ble-pinctrl.dtsi:48 */
			};
		};

		/* node '/pin-controller/spi2_default' defined in zephyr\boards\arduino\nano_33_ble\arduino_nano_33_ble-pinctrl.dtsi:52 */
		spi2_default: spi2_default {
			phandle = < 0xe >; /* in zephyr\boards\arduino\nano_33_ble\arduino_nano_33_ble-common.dtsi:194 */

			/* node '/pin-controller/spi2_default/group1' defined in zephyr\boards\arduino\nano_33_ble\arduino_nano_33_ble-pinctrl.dtsi:53 */
			group1 {
				psels = < 0x400000d >,
				        < 0x5000021 >,
				        < 0x6000028 >; /* in zephyr\boards\arduino\nano_33_ble\arduino_nano_33_ble-pinctrl.dtsi:54 */
			};
		};

		/* node '/pin-controller/spi2_sleep' defined in zephyr\boards\arduino\nano_33_ble\arduino_nano_33_ble-pinctrl.dtsi:60 */
		spi2_sleep: spi2_sleep {
			phandle = < 0xf >; /* in zephyr\boards\arduino\nano_33_ble\arduino_nano_33_ble-common.dtsi:195 */

			/* node '/pin-controller/spi2_sleep/group1' defined in zephyr\boards\arduino\nano_33_ble\arduino_nano_33_ble-pinctrl.dtsi:61 */
			group1 {
				psels = < 0x400000d >,
				        < 0x5000021 >,
				        < 0x6000028 >; /* in zephyr\boards\arduino\nano_33_ble\arduino_nano_33_ble-pinctrl.dtsi:62 */
				low-power-enable;      /* in zephyr\boards\arduino\nano_33_ble\arduino_nano_33_ble-pinctrl.dtsi:65 */
			};
		};

		/* node '/pin-controller/pwm0_default' defined in zephyr\boards\arduino\nano_33_ble\arduino_nano_33_ble-pinctrl.dtsi:69 */
		pwm0_default: pwm0_default {
			phandle = < 0x8 >; /* in zephyr\boards\arduino\nano_33_ble\arduino_nano_33_ble-common.dtsi:217 */

			/* node '/pin-controller/pwm0_default/group1' defined in zephyr\boards\arduino\nano_33_ble\arduino_nano_33_ble-pinctrl.dtsi:70 */
			group1 {
				psels = < 0x16000018 >,
				        < 0x17000010 >,
				        < 0x18000006 >; /* in zephyr\boards\arduino\nano_33_ble\arduino_nano_33_ble-pinctrl.dtsi:71 */
				nordic,invert;          /* in zephyr\boards\arduino\nano_33_ble\arduino_nano_33_ble-pinctrl.dtsi:74 */
			};
		};

		/* node '/pin-controller/pwm0_sleep' defined in zephyr\boards\arduino\nano_33_ble\arduino_nano_33_ble-pinctrl.dtsi:78 */
		pwm0_sleep: pwm0_sleep {
			phandle = < 0x9 >; /* in zephyr\boards\arduino\nano_33_ble\arduino_nano_33_ble-common.dtsi:218 */

			/* node '/pin-controller/pwm0_sleep/group1' defined in zephyr\boards\arduino\nano_33_ble\arduino_nano_33_ble-pinctrl.dtsi:79 */
			group1 {
				psels = < 0x16000018 >,
				        < 0x17000010 >,
				        < 0x18000006 >; /* in zephyr\boards\arduino\nano_33_ble\arduino_nano_33_ble-pinctrl.dtsi:80 */
				low-power-enable;       /* in zephyr\boards\arduino\nano_33_ble\arduino_nano_33_ble-pinctrl.dtsi:83 */
			};
		};

		/* node '/pin-controller/pwm1_default' defined in zephyr\boards\arduino\nano_33_ble\arduino_nano_33_ble-pinctrl.dtsi:87 */
		pwm1_default: pwm1_default {
			phandle = < 0xa >; /* in zephyr\boards\arduino\nano_33_ble\arduino_nano_33_ble-common.dtsi:224 */

			/* node '/pin-controller/pwm1_default/group1' defined in zephyr\boards\arduino\nano_33_ble\arduino_nano_33_ble-pinctrl.dtsi:88 */
			group1 {
				psels = < 0x16000029 >; /* in zephyr\boards\arduino\nano_33_ble\arduino_nano_33_ble-pinctrl.dtsi:89 */
			};
		};

		/* node '/pin-controller/pwm1_sleep' defined in zephyr\boards\arduino\nano_33_ble\arduino_nano_33_ble-pinctrl.dtsi:93 */
		pwm1_sleep: pwm1_sleep {
			phandle = < 0xb >; /* in zephyr\boards\arduino\nano_33_ble\arduino_nano_33_ble-common.dtsi:225 */

			/* node '/pin-controller/pwm1_sleep/group1' defined in zephyr\boards\arduino\nano_33_ble\arduino_nano_33_ble-pinctrl.dtsi:94 */
			group1 {
				psels = < 0x16000029 >; /* in zephyr\boards\arduino\nano_33_ble\arduino_nano_33_ble-pinctrl.dtsi:95 */
			};
		};

		/* node '/pin-controller/pdm0_default' defined in zephyr\boards\arduino\nano_33_ble\arduino_nano_33_ble-pinctrl.dtsi:99 */
		pdm0_default: pdm0_default {

			/* node '/pin-controller/pdm0_default/group1' defined in zephyr\boards\arduino\nano_33_ble\arduino_nano_33_ble-pinctrl.dtsi:100 */
			group1 {
				psels = < 0x1400001a >,
				        < 0x15000019 >; /* in zephyr\boards\arduino\nano_33_ble\arduino_nano_33_ble-pinctrl.dtsi:101 */
			};
		};

		/* node '/pin-controller/pdm0_sleep' defined in zephyr\boards\arduino\nano_33_ble\arduino_nano_33_ble-pinctrl.dtsi:106 */
		pdm0_sleep: pdm0_sleep {

			/* node '/pin-controller/pdm0_sleep/group1' defined in zephyr\boards\arduino\nano_33_ble\arduino_nano_33_ble-pinctrl.dtsi:107 */
			group1 {
				psels = < 0x1400001a >,
				        < 0x15000019 >; /* in zephyr\boards\arduino\nano_33_ble\arduino_nano_33_ble-pinctrl.dtsi:108 */
				low-power-enable;       /* in zephyr\boards\arduino\nano_33_ble\arduino_nano_33_ble-pinctrl.dtsi:110 */
			};
		};

		/* node '/pin-controller/pwm2_default' defined in zephyr\boards\arduino\nano_33_ble\arduino_nano_33_ble-pinctrl.dtsi:114 */
		pwm2_default: pwm2_default {
			phandle = < 0xc >; /* in zephyr\boards\arduino\nano_33_ble\arduino_nano_33_ble-common.dtsi:232 */

			/* node '/pin-controller/pwm2_default/group1' defined in zephyr\boards\arduino\nano_33_ble\arduino_nano_33_ble-pinctrl.dtsi:115 */
			group1 {
				psels = < 0x1600000d >; /* in zephyr\boards\arduino\nano_33_ble\arduino_nano_33_ble-pinctrl.dtsi:116 */
			};
		};

		/* node '/pin-controller/pwm2_sleep' defined in zephyr\boards\arduino\nano_33_ble\arduino_nano_33_ble-pinctrl.dtsi:120 */
		pwm2_sleep: pwm2_sleep {
			phandle = < 0xd >; /* in zephyr\boards\arduino\nano_33_ble\arduino_nano_33_ble-common.dtsi:233 */

			/* node '/pin-controller/pwm2_sleep/group1' defined in zephyr\boards\arduino\nano_33_ble\arduino_nano_33_ble-pinctrl.dtsi:121 */
			group1 {
				psels = < 0x1600000d >; /* in zephyr\boards\arduino\nano_33_ble\arduino_nano_33_ble-pinctrl.dtsi:122 */
				low-power-enable;       /* in zephyr\boards\arduino\nano_33_ble\arduino_nano_33_ble-pinctrl.dtsi:123 */
			};
		};
	};

	/* node '/entropy_bt_hci' defined in zephyr\dts\vendor\nordic\nrf_common.dtsi:34 */
	rng_hci: entropy_bt_hci {
		compatible = "zephyr,bt-hci-entropy"; /* in zephyr\dts\vendor\nordic\nrf_common.dtsi:35 */
		status = "disabled";                  /* in zephyr\dts\vendor\nordic\nrf_common.dtsi:36 */
	};

	/* node '/sw-pwm' defined in zephyr\dts\vendor\nordic\nrf_common.dtsi:39 */
	sw_pwm: sw-pwm {
		compatible = "nordic,nrf-sw-pwm"; /* in zephyr\dts\vendor\nordic\nrf_common.dtsi:40 */
		status = "disabled";              /* in zephyr\dts\vendor\nordic\nrf_common.dtsi:41 */
		generator = < &timer1 >;          /* in zephyr\dts\vendor\nordic\nrf_common.dtsi:42 */
		clock-prescaler = < 0x0 >;        /* in zephyr\dts\vendor\nordic\nrf_common.dtsi:43 */
		#pwm-cells = < 0x3 >;             /* in zephyr\dts\vendor\nordic\nrf_common.dtsi:44 */
	};

	/* node '/cpus' defined in zephyr\dts\arm\nordic\nrf52840.dtsi:15 */
	cpus {
		#address-cells = < 0x1 >; /* in zephyr\dts\arm\nordic\nrf52840.dtsi:16 */
		#size-cells = < 0x0 >;    /* in zephyr\dts\arm\nordic\nrf52840.dtsi:17 */

		/* node '/cpus/cpu@0' defined in zephyr\dts\arm\nordic\nrf52840.dtsi:19 */
		cpu@0 {
			device_type = "cpu";           /* in zephyr\dts\arm\nordic\nrf52840.dtsi:20 */
			compatible = "arm,cortex-m4f"; /* in zephyr\dts\arm\nordic\nrf52840.dtsi:21 */
			reg = < 0x0 >;                 /* in zephyr\dts\arm\nordic\nrf52840.dtsi:22 */
			#address-cells = < 0x1 >;      /* in zephyr\dts\arm\nordic\nrf52840.dtsi:23 */
			#size-cells = < 0x1 >;         /* in zephyr\dts\arm\nordic\nrf52840.dtsi:24 */

			/* node '/cpus/cpu@0/itm@e0000000' defined in zephyr\dts\arm\nordic\nrf52840.dtsi:26 */
			itm: itm@e0000000 {
				compatible = "arm,armv7m-itm";     /* in zephyr\dts\arm\nordic\nrf52840.dtsi:27 */
				reg = < 0xe0000000 0x1000 >;       /* in zephyr\dts\arm\nordic\nrf52840.dtsi:28 */
				swo-ref-frequency = < 0x1e84800 >; /* in zephyr\dts\arm\nordic\nrf52840.dtsi:29 */
			};
		};
	};

	/* node '/clocks' defined in zephyr\dts\arm\nordic\nrf52840.dtsi:34 */
	clocks {

		/* node '/clocks/hfxo' defined in zephyr\dts\arm\nordic\nrf52840.dtsi:35 */
		hfxo: hfxo {
			compatible = "nordic,nrf52-hfxo"; /* in zephyr\dts\arm\nordic\nrf52840.dtsi:36 */
			clock-frequency = < 0x3d09000 >;  /* in zephyr\dts\arm\nordic\nrf52840.dtsi:37 */
			startup-time-us = < 0x578 >;      /* in zephyr\dts\arm\nordic\nrf52840.dtsi:38 */
			#clock-cells = < 0x0 >;           /* in zephyr\dts\arm\nordic\nrf52840.dtsi:39 */
		};
	};

	/* node '/leds' defined in zephyr\boards\arduino\nano_33_ble\arduino_nano_33_ble-common.dtsi:20 */
	leds {
		compatible = "gpio-leds"; /* in zephyr\boards\arduino\nano_33_ble\arduino_nano_33_ble-common.dtsi:21 */

		/* node '/leds/led_0' defined in zephyr\boards\arduino\nano_33_ble\arduino_nano_33_ble-common.dtsi:23 */
		led0: led_0 {
			gpios = < &gpio0 0x18 0x1 >; /* in zephyr\boards\arduino\nano_33_ble\arduino_nano_33_ble-common.dtsi:24 */
			label = "Red LED";           /* in zephyr\boards\arduino\nano_33_ble\arduino_nano_33_ble-common.dtsi:25 */
		};

		/* node '/leds/led_1' defined in zephyr\boards\arduino\nano_33_ble\arduino_nano_33_ble-common.dtsi:28 */
		led1: led_1 {
			gpios = < &gpio0 0x10 0x1 >; /* in zephyr\boards\arduino\nano_33_ble\arduino_nano_33_ble-common.dtsi:29 */
			label = "Green LED";         /* in zephyr\boards\arduino\nano_33_ble\arduino_nano_33_ble-common.dtsi:30 */
		};

		/* node '/leds/led_2' defined in zephyr\boards\arduino\nano_33_ble\arduino_nano_33_ble-common.dtsi:33 */
		led2: led_2 {
			gpios = < &gpio0 0x6 0x1 >; /* in zephyr\boards\arduino\nano_33_ble\arduino_nano_33_ble-common.dtsi:34 */
			label = "Blue LED";         /* in zephyr\boards\arduino\nano_33_ble\arduino_nano_33_ble-common.dtsi:35 */
		};

		/* node '/leds/led_3' defined in zephyr\boards\arduino\nano_33_ble\arduino_nano_33_ble-common.dtsi:38 */
		led3: led_3 {
			gpios = < &gpio0 0xd 0x0 >; /* in zephyr\boards\arduino\nano_33_ble\arduino_nano_33_ble-common.dtsi:40 */
			label = "Yellow LED";       /* in zephyr\boards\arduino\nano_33_ble\arduino_nano_33_ble-common.dtsi:41 */
		};

		/* node '/leds/led_4' defined in zephyr\boards\arduino\nano_33_ble\arduino_nano_33_ble-common.dtsi:44 */
		led4: led_4 {
			gpios = < &gpio1 0x9 0x0 >; /* in zephyr\boards\arduino\nano_33_ble\arduino_nano_33_ble-common.dtsi:45 */
			label = "User LED";         /* in zephyr\boards\arduino\nano_33_ble\arduino_nano_33_ble-common.dtsi:46 */
		};
	};

	/* node '/pwmleds' defined in zephyr\boards\arduino\nano_33_ble\arduino_nano_33_ble-common.dtsi:50 */
	pwmleds {
		compatible = "pwm-leds"; /* in zephyr\boards\arduino\nano_33_ble\arduino_nano_33_ble-common.dtsi:51 */

		/* node '/pwmleds/led_pwm_0' defined in zephyr\boards\arduino\nano_33_ble\arduino_nano_33_ble-common.dtsi:53 */
		red_pwm_led: led_pwm_0 {
			pwms = < &pwm0 0x0 0x1312d00 0x1 >; /* in zephyr\boards\arduino\nano_33_ble\arduino_nano_33_ble-common.dtsi:54 */
			label = "Red PWM LED";              /* in zephyr\boards\arduino\nano_33_ble\arduino_nano_33_ble-common.dtsi:55 */
		};

		/* node '/pwmleds/led_pwm_1' defined in zephyr\boards\arduino\nano_33_ble\arduino_nano_33_ble-common.dtsi:58 */
		green_pwm_led: led_pwm_1 {
			pwms = < &pwm0 0x1 0x1312d00 0x1 >; /* in zephyr\boards\arduino\nano_33_ble\arduino_nano_33_ble-common.dtsi:59 */
			label = "Green PWM LED";            /* in zephyr\boards\arduino\nano_33_ble\arduino_nano_33_ble-common.dtsi:60 */
		};

		/* node '/pwmleds/led_pwm_2' defined in zephyr\boards\arduino\nano_33_ble\arduino_nano_33_ble-common.dtsi:63 */
		blue_pwm_led: led_pwm_2 {
			pwms = < &pwm0 0x2 0x1312d00 0x1 >; /* in zephyr\boards\arduino\nano_33_ble\arduino_nano_33_ble-common.dtsi:64 */
			label = "Blue PWM LED";             /* in zephyr\boards\arduino\nano_33_ble\arduino_nano_33_ble-common.dtsi:65 */
		};

		/* node '/pwmleds/led_pwm_4' defined in zephyr\boards\arduino\nano_33_ble\arduino_nano_33_ble-common.dtsi:68 */
		user_pwm_led: led_pwm_4 {
			pwms = < &pwm1 0x0 0x1312d00 0x0 >; /* in zephyr\boards\arduino\nano_33_ble\arduino_nano_33_ble-common.dtsi:69 */
			label = "User PWM LED";             /* in zephyr\boards\arduino\nano_33_ble\arduino_nano_33_ble-common.dtsi:70 */
		};
	};

	/* node '/pwmleds2' defined in zephyr\boards\arduino\nano_33_ble\arduino_nano_33_ble-common.dtsi:74 */
	pwmleds2 {
		compatible = "pwm-leds"; /* in zephyr\boards\arduino\nano_33_ble\arduino_nano_33_ble-common.dtsi:75 */
		status = "disabled";     /* in zephyr\boards\arduino\nano_33_ble\arduino_nano_33_ble-common.dtsi:77 */

		/* node '/pwmleds2/led_pwm_3' defined in zephyr\boards\arduino\nano_33_ble\arduino_nano_33_ble-common.dtsi:79 */
		yellow_pwm_led: led_pwm_3 {
			pwms = < &pwm2 0x0 0x1312d00 0x0 >; /* in zephyr\boards\arduino\nano_33_ble\arduino_nano_33_ble-common.dtsi:80 */
			label = "Yellow PWM LED";           /* in zephyr\boards\arduino\nano_33_ble\arduino_nano_33_ble-common.dtsi:81 */
		};
	};

	/* node '/vdd-env' defined in zephyr\boards\arduino\nano_33_ble\arduino_nano_33_ble-common.dtsi:85 */
	vdd_env: vdd-env {
		compatible = "regulator-fixed";     /* in zephyr\boards\arduino\nano_33_ble\arduino_nano_33_ble-common.dtsi:86 */
		regulator-name = "vdd_env";         /* in zephyr\boards\arduino\nano_33_ble\arduino_nano_33_ble-common.dtsi:87 */
		enable-gpios = < &gpio0 0x16 0x0 >; /* in zephyr\boards\arduino\nano_33_ble\arduino_nano_33_ble-common.dtsi:88 */
		regulator-boot-on;                  /* in zephyr\boards\arduino\nano_33_ble\arduino_nano_33_ble-common.dtsi:89 */
		startup-delay-us = < 0x1388 >;      /* in zephyr\boards\arduino\nano_33_ble\arduino_nano_33_ble-common.dtsi:90 */
	};

	/* node '/zephyr,user' defined in zephyr\boards\arduino\nano_33_ble\arduino_nano_33_ble-common.dtsi:93 */
	zephyr,user {
		pull-up-gpios = < &gpio1 0x0 0x0 >; /* in zephyr\boards\arduino\nano_33_ble\arduino_nano_33_ble-common.dtsi:95 */
	};

	/* node '/connector' defined in zephyr\boards\arduino\nano_33_ble\arduino_nano_connector.dtsi:9 */
	arduino_nano_header: connector {
		compatible = "arduino-nano-header";        /* in zephyr\boards\arduino\nano_33_ble\arduino_nano_connector.dtsi:10 */
		#gpio-cells = < 0x2 >;                     /* in zephyr\boards\arduino\nano_33_ble\arduino_nano_connector.dtsi:11 */
		gpio-map-mask = < 0xffffffff 0xffffffc0 >; /* in zephyr\boards\arduino\nano_33_ble\arduino_nano_connector.dtsi:12 */
		gpio-map-pass-thru = < 0x0 0x3f >;         /* in zephyr\boards\arduino\nano_33_ble\arduino_nano_connector.dtsi:13 */
		gpio-map = < 0x0 0x0 &gpio1 0x3 0x0 >,
		           < 0x1 0x0 &gpio1 0xa 0x0 >,
		           < 0x2 0x0 &gpio1 0xb 0x0 >,
		           < 0x3 0x0 &gpio1 0xc 0x0 >,
		           < 0x4 0x0 &gpio1 0xf 0x0 >,
		           < 0x5 0x0 &gpio1 0xd 0x0 >,
		           < 0x6 0x0 &gpio1 0xe 0x0 >,
		           < 0x7 0x0 &gpio0 0x17 0x0 >,
		           < 0x8 0x0 &gpio0 0x15 0x0 >,
		           < 0x9 0x0 &gpio0 0x1b 0x0 >,
		           < 0xa 0x0 &gpio1 0x2 0x0 >,
		           < 0xb 0x0 &gpio1 0x1 0x0 >,
		           < 0xc 0x0 &gpio1 0x8 0x0 >,
		           < 0xd 0x0 &gpio0 0xd 0x0 >,
		           < 0xe 0x0 &gpio0 0x4 0x0 >,
		           < 0xf 0x0 &gpio0 0x5 0x0 >,
		           < 0x10 0x0 &gpio0 0x1e 0x0 >,
		           < 0x11 0x0 &gpio0 0x1d 0x0 >,
		           < 0x12 0x0 &gpio0 0x1f 0x0 >,
		           < 0x13 0x0 &gpio0 0x2 0x0 >,
		           < 0x14 0x0 &gpio0 0x1c 0x0 >,
		           < 0x15 0x0 &gpio0 0x3 0x0 >;    /* in zephyr\boards\arduino\nano_33_ble\arduino_nano_connector.dtsi:14 */
	};
};
